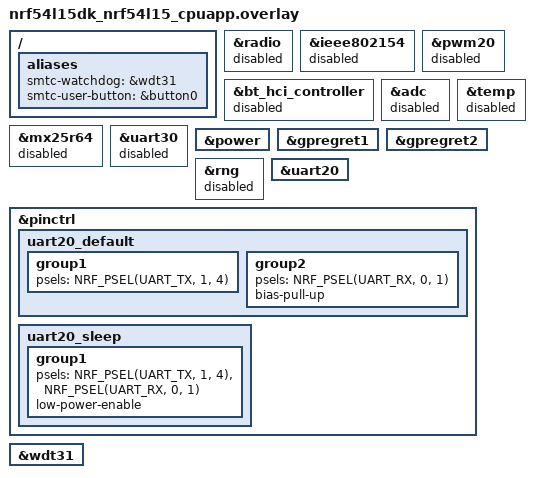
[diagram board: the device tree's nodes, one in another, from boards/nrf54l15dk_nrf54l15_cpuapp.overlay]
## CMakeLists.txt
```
# Copyright (c) 2024 Semtech Corporation
# SPDX-License-Identifier: Apache-2.0

cmake_minimum_required(VERSION 3.13.1)

find_package(Zephyr REQUIRED HINTS $ENV{ZEPHYR_BASE})
project(full_almanac_update)

target_sources(app PRIVATE
  ${CMAKE_CURRENT_SOURCE_DIR}/src/main.c
  ${CMAKE_CURRENT_SOURCE_DIR}/../geolocation/src/geolocation_bsp.c
  ${ZEPHYR_USP_MODULE_DIR}/examples/main_examples/geolocation/full_almanac_update/app_full_almanac_update.c
)

zephyr_include_directories(
  ${CMAKE_CURRENT_SOURCE_DIR}/src
  ${ZEPHYR_USP_MODULE_DIR}/examples/main_examples/geolocation/full_almanac_update/
)

# Apply the same compile definitions as LBM library
# Link against the INTERFACE library that contains all LBM compile definitions
target_link_libraries(app PRIVATE lbm_compile_definitions)
```

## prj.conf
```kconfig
# Copyright (c) 2024 Semtech Corporation
# SPDX-License-Identifier: Apache-2.0

# --------------------------- General configuration ---------------------------

CONFIG_USE_SEGGER_RTT=n

# heap size
CONFIG_HEAP_MEM_POOL_SIZE=4096

# log
CONFIG_LOG=y
CONFIG_LOG_BACKEND_SHOW_COLOR=n # Set it to 'y' to enable color formatting on output messages

CONFIG_TEST_RANDOM_GENERATOR=y

CONFIG_PM_DEVICE=y

CONFIG_WATCHDOG=n

CONFIG_FLASH=y

# ------------------------------ Transceiver driver ----------------------------

CONFIG_LORA_BASICS_MODEM_DRIVERS=y
# We chose to disable intermediate thread between IRQ and USP RAC Thread to make timestamping is as fast as possible
CONFIG_LORA_BASICS_MODEM_DRIVERS_EVENT_TRIGGER_NO_THREAD=y
#CONFIG_LORA_BASICS_MODEM_DRIVERS_EVENT_TRIGGER_GLOBAL_THREAD=n
#CONFIG_LORA_BASICS_MODEM_DRIVERS_EVENT_TRIGGER_OWN_THREAD=n

# ------------------------------ LoRa Basics Modem -----------------------------

CONFIG_LORA_BASICS_MODEM_GEOLOCATION=y

# ------------------------------ USP -----------------------------

CONFIG_USP_LORA_BASICS_MODEM=y
CONFIG_USP=y
CONFIG_USP_MAIN_THREAD=n

#CONFIG_USP_LOG_LEVEL_DBG=y

CONFIG_LOG_BUFFER_SIZE=4096

# CONFIG_CLOCK_CONTROL=y
# CONFIG_CLOCK_CONTROL_NRF=y

# Threads are cooperative (non-preemptive) to simplify critical section management and avoid complex synchronization.
# This approach may reduce reactivity when ISR (interrupt service routines) are triggered (low optimization)
# The USP RAC thread is assigned a higher priority: it will execute immediately once the Main thread yields or blocks, ensuring prompt handling of USP RAC-related tasks.
# The Main thread has a lower priority: it runs only when the USP RAC thread is idle or waiting
CONFIG_MAIN_THREAD_PRIORITY=-2
CONFIG_USP_MAIN_THREAD_PRIORITY=-4

# Threads are preemptive: a thread with a higher priority can interrupt (preempt) a lower priority thread at any time.
# USP RAC thread has higher priority (1): it will preempt the main thread immediately whenever it is ready to run (ISR/Timer), ensuring low latency and fast response for USP RAC-related tasks.
# Main thread has lower priority (3): it runs only when the USP RAC thread is not active, yielding CPU time to the more urgent USP RAC operations automatically.
# This priority scheme allows responsive multitasking with guaranteed preemption based on thread priority.
# CONFIG_MAIN_THREAD_PRIORITY=3
# CONFIG_USP_MAIN_THREAD_PRIORITY=1
# CONFIG_USP_THREADS_MUTEXES=y
#
# Priority Inversion : In case of multiple threads with different priorities, consider the modification of existing priorities and mutex use, or use Zephyr capabilities :
# CONFIG_KERNEL_MEM_POOL=y
# CONFIG_MUTEX_PRIORITY_INHERITANCE=y
# CONFIG_PRIORITY_CEILING=y

# Only one thread
# CONFIG_USP_MAIN_THREAD_PRIORITY=0

# Stack
CONFIG_MAIN_STACK_SIZE=4096
CONFIG_STACK_SENTINEL=y

# Debug stack (à enlever en production)
CONFIG_THREAD_STACK_INFO=y
CONFIG_STACK_SENTINEL=y
CONFIG_THREAD_MONITOR=y
CONFIG_THREAD_NAME=y

# ------------------------------ Power management -----------------------------

# CONFIG_PM=y

# CONFIG_LOG=n
# CONFIG_SERIAL=n
# CONFIG_CONSOLE=n
# CONFIG_UART_CONSOLE=n
# CONFIG_PRINTK=n
# CONFIG_STDOUT_CONSOLE=n

CONFIG_PM_DEVICE_POWER_DOMAIN=y
# CONFIG_PM_DEVICE_RUNTIME=y


# ------------------------------ Debug -----------------------------
CONFIG_DEBUG=y
CONFIG_NO_OPTIMIZATIONS=y
CONFIG_DEBUG_OPTIMIZATIONS=y
CONFIG_DEBUG_THREAD_INFO=y
CONFIG_DCACHE=n
```

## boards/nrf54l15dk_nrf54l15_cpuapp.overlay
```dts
// /*
//  * Copyright (c) 2024 Semtech Corporation
//  *
//  * SPDX-License-Identifier: Apache-2.0
//  */

/ {
	aliases {
		smtc-watchdog = &wdt31;
		smtc-user-button = &button0;
	};
};

&radio {
	status = "disabled";
};

&ieee802154 {
	status = "disabled";
};

&bt_hci_controller {
	status = "disabled";
};

&pwm20 {
	status = "disabled";
};

&adc {
	status = "disabled";
};

&temp {
	status = "disabled";
};

&mx25r64 {
	status = "disabled";
};


// &rng_hci {
	//     status = "disabled";
// };

&uart30 {
	status = "disabled";
};

// &clock {
	//     status = "disabled"; //For some reason, disabling it increases power consumption
// };

&power {
	status = "okay";
};

&gpregret1 {
	status = "okay";
};

&gpregret2 {
	status = "okay";
};

&rng {
	status = "disabled";
};

// &spi00 {
	//     status = "disabled";
// };


&uart20 {
	status = "okay";
	// disable-rx; //Disabling RX allows a gain of ~200µA, totally disabling uart allows another gain of ~200µA
	// /delete-property/ hw-flow-control;
};

&pinctrl {
	uart20_default: uart20_default {
		group1 {
			psels = <NRF_PSEL(UART_TX, 1, 4)>
			// ,<NRF_PSEL(UART_RTS, 0, 2)>
			;
		};
		group2 {
			psels = <NRF_PSEL(UART_RX, 0, 1)> //DIO9 is mapped on RX
			// ,<NRF_PSEL(UART_CTS, 0, 3)>
			;
			bias-pull-up;
		};
	};

	uart20_sleep: uart20_sleep {
		group1 {
			psels = <NRF_PSEL(UART_TX, 1, 4)>,
					<NRF_PSEL(UART_RX, 0, 1)>
					// ,<NRF_PSEL(UART_RTS, 0, 2)>
					// ,<NRF_PSEL(UART_CTS, 0, 3)>
					;
			low-power-enable;
		};
	};
};

&wdt31 {
	status = "okay";
};
```

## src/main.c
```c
/**
 * @file      main.c
 *
 * @brief     Application main
 *
 * The Clear BSD License
 * Copyright Semtech Corporation 2025. All rights reserved.
 *
 * Redistribution and use in source and binary forms, with or without
 * modification, are permitted (subject to the limitations in the disclaimer
 * below) provided that the following conditions are met:
 *     * Redistributions of source code must retain the above copyright
 *       notice, this list of conditions and the following disclaimer.
 *     * Redistributions in binary form must reproduce the above copyright
 *       notice, this list of conditions and the following disclaimer in the
 *       documentation and/or other materials provided with the distribution.
 *     * Neither the name of the Semtech corporation nor the
 *       names of its contributors may be used to endorse or promote products
 *       derived from this software without specific prior written permission.
 *
 * NO EXPRESS OR IMPLIED LICENSES TO ANY PARTY'S PATENT RIGHTS ARE GRANTED BY
 * THIS LICENSE. THIS SOFTWARE IS PROVIDED BY THE COPYRIGHT HOLDERS AND
 * CONTRIBUTORS "AS IS" AND ANY EXPRESS OR IMPLIED WARRANTIES, INCLUDING, BUT
 * NOT LIMITED TO, THE IMPLIED WARRANTIES OF MERCHANTABILITY AND FITNESS FOR A
 * PARTICULAR PURPOSE ARE DISCLAIMED. IN NO EVENT SHALL SEMTECH CORPORATION BE
 * LIABLE FOR ANY DIRECT, INDIRECT, INCIDENTAL, SPECIAL, EXEMPLARY, OR
 * CONSEQUENTIAL DAMAGES (INCLUDING, BUT NOT LIMITED TO, PROCUREMENT OF
 * SUBSTITUTE GOODS OR SERVICES; LOSS OF USE, DATA, OR PROFITS; OR BUSINESS
 * INTERRUPTION) HOWEVER CAUSED AND ON ANY THEORY OF LIABILITY, WHETHER IN
 * CONTRACT, STRICT LIABILITY, OR TORT (INCLUDING NEGLIGENCE OR OTHERWISE)
 * ARISING IN ANY WAY OUT OF THE USE OF THIS SOFTWARE, EVEN IF ADVISED OF THE
 * POSSIBILITY OF SUCH DAMAGE.
 */

#include <time.h>

#include <zephyr/kernel.h>
#include <zephyr/logging/log.h>
#include <zephyr/drivers/gpio.h>
#include <zephyr/lorawan_lbm/lorawan_hal_init.h>

#include <smtc_modem_api.h>
#include <smtc_modem_utilities.h>
#include <smtc_modem_hal.h>
#include <smtc_modem_geolocation_api.h>

#include <smtc_sw_platform_helper.h>
#include <smtc_modem_helper.h>
#define SMTC_HAL_DBG_TRACE_C
#include <smtc_hal_dbg_trace.h>
#include <smtc_rac_api.h>

#include "app_full_almanac_update.h"

LOG_MODULE_REGISTER( full_almanac_update, LOG_LEVEL_INF );

/*
 * -----------------------------------------------------------------------------
 * --- PRIVATE CONSTANTS -------------------------------------------------------
 */

/**
 * @brief Watchdog counter reload value during sleep (The period must be lower than MCU watchdog
 * period (here 32s))
 */
#define WATCHDOG_RELOAD_PERIOD_MS 20000

#define TIME_BUFFER_SIZE ( 80 )

#define OFFSET_BETWEEN_GPS_EPOCH_AND_UNIX_EPOCH ( 315964800 )

/*
 * -----------------------------------------------------------------------------
 * --- PRIVATE TYPES -----------------------------------------------------------
 */

/*
 * -----------------------------------------------------------------------------
 * --- PRIVATE VARIABLES -------------------------------------------------------
 */

static const struct gpio_dt_spec rx_led = GPIO_DT_SPEC_GET( DT_PATH( leds, lr11xx_rx_led ), gpios );
static const struct gpio_dt_spec tx_led = GPIO_DT_SPEC_GET( DT_PATH( leds, lr11xx_tx_led ), gpios );

/*
 * -----------------------------------------------------------------------------
 * --- PRIVATE FUNCTIONS DECLARATION -------------------------------------------
 */

/**
 * Stack id value (multistacks modem is not yet available)
 */
#define STACK_ID 0

/**
 * @brief User callback for modem event
 *
 *  This callback is called every time an event ( see smtc_modem_event_t ) appears in the modem.
 *  Several events may have to be read from the modem when this callback is called.
 */
static void modem_event_callback( void );

/*
 * -----------------------------------------------------------------------------
 * --- PUBLIC FUNCTIONS DEFINITION ---------------------------------------------
 */

/**
 * @brief Example to flash full almanac to LR11XX
 *
 */
int main( void )
{
    gpio_pin_configure_dt( &rx_led, GPIO_OUTPUT_INACTIVE );
    gpio_pin_configure_dt( &tx_led, GPIO_OUTPUT_INACTIVE );

    LOG_INF( "Full almanac flasher example" );

    SMTC_SW_PLATFORM_INIT( );
    SMTC_SW_PLATFORM_VOID( smtc_rac_init( ) );
    SMTC_SW_PLATFORM_VOID( smtc_modem_init( &modem_event_callback ) );

    while( true )
    {
        uint32_t sleep_time_ms = smtc_modem_run_engine( );
        smtc_rac_run_engine( );
        if( smtc_rac_is_irq_flag_pending( ) )
        {
            continue;
        }
        k_sem_take( smtc_modem_hal_get_event_sem( ), K_MSEC( MIN( sleep_time_ms, WATCHDOG_RELOAD_PERIOD_MS ) ) );
    }

    return 0;
}

//  WARNING : Run in USP/RAC Thread if compiled with threads
static void modem_event_callback( void )
{
    LOG_DBG( "Modem event callback" );

    smtc_modem_event_t current_event = { 0 };
    uint8_t            stack_id      = STACK_ID;
    uint8_t            event_pending_count;

    /* Continue to read modem event until all event has been processed */
    do
    {
        /* Read modem event */
        ASSERT_SMTC_MODEM_RC( smtc_modem_get_event( &current_event, &event_pending_count ) );

        switch( current_event.event_type )
        {
        case SMTC_MODEM_EVENT_RESET:
            SMTC_HAL_TRACE_INFO( "Event received: RESET\n" );
            if( check_lr11xx_fw_version( transceiver ) != true )
            {
                SMTC_HAL_TRACE_ERROR( "LR11xx firmware version is not compatible with this example\n" );
                break;
            }
            almanac_full_update( stack_id );

            break;

        default:
            LOG_ERR( "Unknown event %u", current_event.event_type );
            break;
        }
    } while( event_pending_count > 0 );
}

/* --- EOF ------------------------------------------------------------------ */
```
